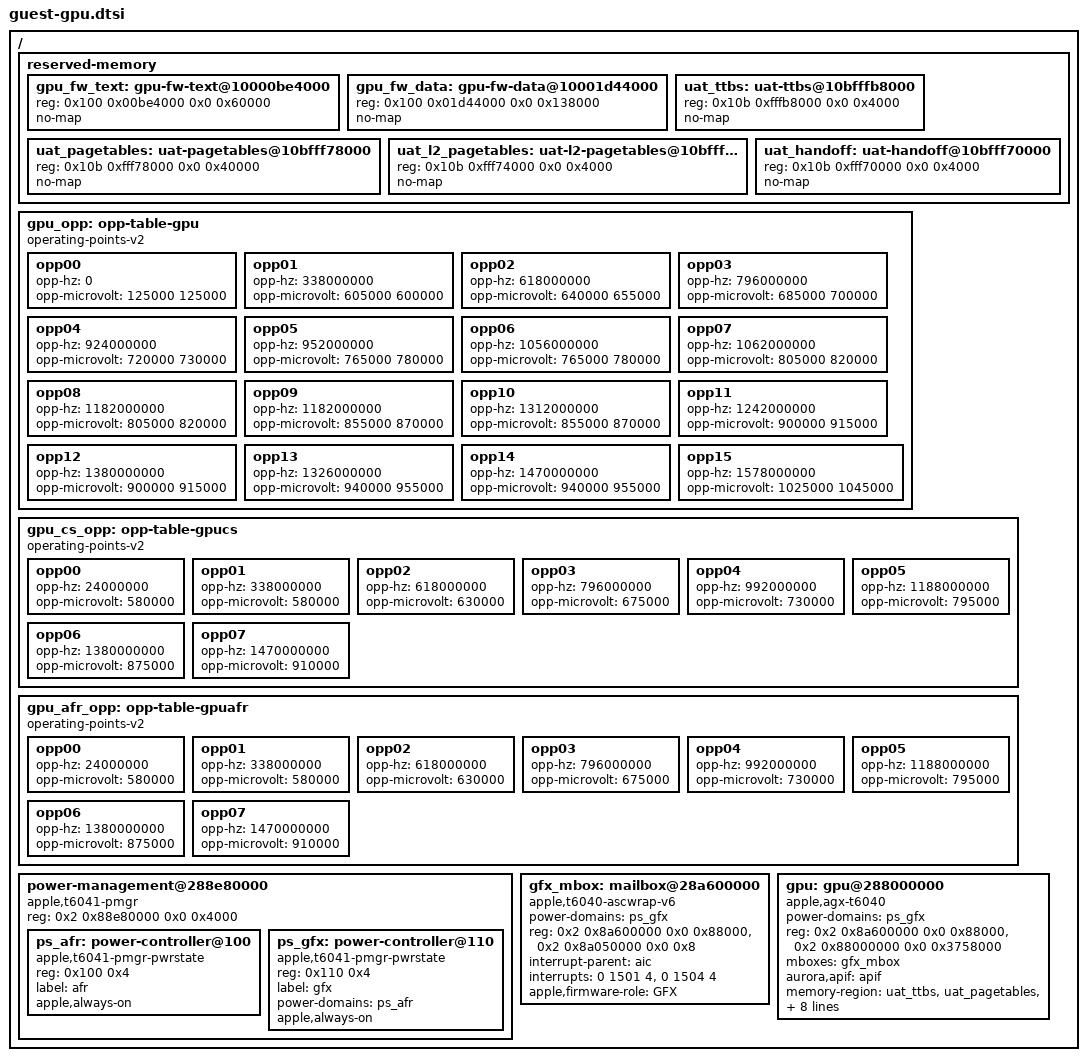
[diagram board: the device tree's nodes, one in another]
// SPDX-License-Identifier: GPL-2.0-only
// guest-gpu.dtsi: GPU for the macho guest. Generated from t6040-j616s.dts; regions are the raw-boot
// ADT values, which the monitor compares with the macho ADT at boot (monitor/gpu.c). Under SPTM the
// driver reaches none of the UAT regions; their names stay because the driver checks their sizes.
// /include/ as the last line of guest-native.dts.
/ {
	reserved-memory {
		gpu_fw_text: gpu-fw-text@10000be4000 {
			reg = <0x100 0x00be4000 0x0 0x60000>;
			no-map;
		};
		gpu_fw_data: gpu-fw-data@10001d44000 {
			reg = <0x100 0x01d44000 0x0 0x138000>;
			no-map;
		};
		uat_ttbs: uat-ttbs@10bfffb8000 {
			reg = <0x10b 0xfffb8000 0x0 0x4000>;
			no-map;
		};
		uat_pagetables: uat-pagetables@10bfff78000 {
			reg = <0x10b 0xfff78000 0x0 0x40000>;
			no-map;
		};
		uat_l2_pagetables: uat-l2-pagetables@10bfff74000 {
			reg = <0x10b 0xfff74000 0x0 0x4000>;
			no-map;
		};
		uat_handoff: uat-handoff@10bfff70000 {
			reg = <0x10b 0xfff70000 0x0 0x4000>;
			no-map;
		};
	};
	gpu_opp: opp-table-gpu {
		compatible = "operating-points-v2";

		opp00 {
			opp-hz = /bits/ 64 <0>;
			opp-microvolt = <125000 125000>;
		};
		opp01 {
			opp-hz = /bits/ 64 <338000000>;
			opp-microvolt = <605000 600000>;
		};
		opp02 {
			opp-hz = /bits/ 64 <618000000>;
			opp-microvolt = <640000 655000>;
		};
		opp03 {
			opp-hz = /bits/ 64 <796000000>;
			opp-microvolt = <685000 700000>;
		};
		opp04 {
			opp-hz = /bits/ 64 <924000000>;
			opp-microvolt = <720000 730000>;
		};
		opp05 {
			opp-hz = /bits/ 64 <952000000>;
			opp-microvolt = <765000 780000>;
		};
		opp06 {
			opp-hz = /bits/ 64 <1056000000>;
			opp-microvolt = <765000 780000>;
		};
		opp07 {
			opp-hz = /bits/ 64 <1062000000>;
			opp-microvolt = <805000 820000>;
		};
		opp08 {
			opp-hz = /bits/ 64 <1182000000>;
			opp-microvolt = <805000 820000>;
		};
		opp09 {
			opp-hz = /bits/ 64 <1182000000>;
			opp-microvolt = <855000 870000>;
		};
		opp10 {
			opp-hz = /bits/ 64 <1312000000>;
			opp-microvolt = <855000 870000>;
		};
		opp11 {
			opp-hz = /bits/ 64 <1242000000>;
			opp-microvolt = <900000 915000>;
		};
		opp12 {
			opp-hz = /bits/ 64 <1380000000>;
			opp-microvolt = <900000 915000>;
		};
		opp13 {
			opp-hz = /bits/ 64 <1326000000>;
			opp-microvolt = <940000 955000>;
		};
		opp14 {
			opp-hz = /bits/ 64 <1470000000>;
			opp-microvolt = <940000 955000>;
		};
		opp15 {
			opp-hz = /bits/ 64 <1578000000>;
			opp-microvolt = <1025000 1045000>;
		};
	};
	gpu_cs_opp: opp-table-gpucs {
		compatible = "operating-points-v2";

		opp00 {
			opp-hz = /bits/ 64 <24000000>;
			opp-microvolt = <580000>;
		};
		opp01 {
			opp-hz = /bits/ 64 <338000000>;
			opp-microvolt = <580000>;
		};
		opp02 {
			opp-hz = /bits/ 64 <618000000>;
			opp-microvolt = <630000>;
		};
		opp03 {
			opp-hz = /bits/ 64 <796000000>;
			opp-microvolt = <675000>;
		};
		opp04 {
			opp-hz = /bits/ 64 <992000000>;
			opp-microvolt = <730000>;
		};
		opp05 {
			opp-hz = /bits/ 64 <1188000000>;
			opp-microvolt = <795000>;
		};
		opp06 {
			opp-hz = /bits/ 64 <1380000000>;
			opp-microvolt = <875000>;
		};
		opp07 {
			opp-hz = /bits/ 64 <1470000000>;
			opp-microvolt = <910000>;
		};
	};
	gpu_afr_opp: opp-table-gpuafr {
		compatible = "operating-points-v2";

		opp00 {
			opp-hz = /bits/ 64 <24000000>;
			opp-microvolt = <580000>;
		};
		opp01 {
			opp-hz = /bits/ 64 <338000000>;
			opp-microvolt = <580000>;
		};
		opp02 {
			opp-hz = /bits/ 64 <618000000>;
			opp-microvolt = <630000>;
		};
		opp03 {
			opp-hz = /bits/ 64 <796000000>;
			opp-microvolt = <675000>;
		};
		opp04 {
			opp-hz = /bits/ 64 <992000000>;
			opp-microvolt = <730000>;
		};
		opp05 {
			opp-hz = /bits/ 64 <1188000000>;
			opp-microvolt = <795000>;
		};
		opp06 {
			opp-hz = /bits/ 64 <1380000000>;
			opp-microvolt = <875000>;
		};
		opp07 {
			opp-hz = /bits/ 64 <1470000000>;
			opp-microvolt = <910000>;
		};
	};
	power-management@288e80000 {
		compatible = "apple,t6041-pmgr", "apple,t8103-pmgr", "syscon", "simple-mfd";
		#address-cells = <1>; #size-cells = <1>;
		reg = <0x2 0x88e80000 0x0 0x4000>;
		ps_afr: power-controller@100 { compatible = "apple,t6041-pmgr-pwrstate", "apple,t8103-pmgr-pwrstate";
			reg = <0x100 0x4>; #power-domain-cells = <0>; #reset-cells = <0>; label = "afr"; apple,always-on; };
		ps_gfx: power-controller@110 { compatible = "apple,t6041-pmgr-pwrstate", "apple,t8103-pmgr-pwrstate";
			reg = <0x110 0x4>; #power-domain-cells = <0>; #reset-cells = <0>; label = "gfx"; power-domains = <&ps_afr>; apple,always-on; };
	};
	gfx_mbox: mailbox@28a600000 {
		power-domains = <&ps_gfx>;
		compatible = "apple,t6040-ascwrap-v6";
		reg = <0x2 0x8a600000 0x0 0x88000>, <0x2 0x8a050000 0x0 0x8>;
		reg-names = "wrapper", "iop-vbar";
		interrupt-parent = <&aic>;
		interrupts = <0 1501 4>, <0 1504 4>;
		interrupt-names = "send-empty", "recv-not-empty";
		apple,firmware-role = "GFX";
		#mbox-cells = <0>;
	};
	gpu: gpu@288000000 {
		power-domains = <&ps_gfx>;
		compatible = "apple,agx-t6040";
		reg = <0x2 0x8a600000 0x0 0x88000>, <0x2 0x88000000 0x0 0x3758000>;
		reg-names = "asc", "sgx";
		mboxes = <&gfx_mbox>;
		aurora,apif = <&apif>;
		memory-region = <&uat_ttbs>, <&uat_pagetables>, <&uat_handoff>,
				<&gpu_fw_data>, <&uat_l2_pagetables>, <&gpu_fw_text>;
		memory-region-names = "ttbs", "pagetables", "handoff", "fw-data",
				      "l2-pagetables", "fw-text";
		operating-points-v2 = <&gpu_opp>;
		apple,cs-opp = <&gpu_cs_opp>;
		apple,afr-opp = <&gpu_afr_opp>;
		apple,firmware-version = <26 6 2>;
		status = "okay";
	};
};
